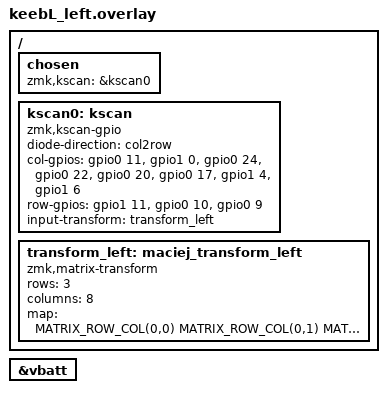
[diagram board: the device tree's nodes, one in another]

/* nice!nano v2 left half: COL2ROW, 3 rows x 8 cols */
#include <dt-bindings/zmk/matrix_transform.h>

&vbatt { status = "okay"; };

/ {
    chosen { zmk,kscan = &kscan0; }

    kscan0: kscan {
        compatible = "zmk,kscan-gpio";
        diode-direction = "col2row";

        /* Left side column pins (from KMK left col_pins) */
        col-gpios = <&gpio0 11 GPIO_ACTIVE_HIGH>,  /* P0.11 */
                    <&gpio1  0 GPIO_ACTIVE_HIGH>,  /* P1.00 */
                    <&gpio0 24 GPIO_ACTIVE_HIGH>,  /* P0.24 */
                    <&gpio0 22 GPIO_ACTIVE_HIGH>,  /* P0.22 */
                    <&gpio0 20 GPIO_ACTIVE_HIGH>,  /* P0.20 */
                    <&gpio0 17 GPIO_ACTIVE_HIGH>,  /* P0.17 */
                    <&gpio1  4 GPIO_ACTIVE_HIGH>,  /* P1.04 */
                    <&gpio1  6 GPIO_ACTIVE_HIGH>;  /* P1.06 */

        /* Left side row pins (from KMK left row_pins) */
        row-gpios = <&gpio1 11 (GPIO_ACTIVE_HIGH | GPIO_PULL_UP)>,  /* P1.11 */
                    <&gpio0 10 (GPIO_ACTIVE_HIGH | GPIO_PULL_UP)>,  /* P0.10 */
                    <&gpio0  9 (GPIO_ACTIVE_HIGH | GPIO_PULL_UP)>;  /* P0.09 */
    };
};

&kscan0 { input-transform = <&transform_left>; };

/ {
    /* Map 20 logical LEFT keys (0..5, 12..17, 24..31) to physical 3x8 */
    transform_left: maciej_transform_left {
        compatible = "zmk,matrix-transform";
        rows = <3>;
        columns = <8>;
        map = <
            /* Row1 L: logical 0..5 -> physical row0 col0..5 */
            MATRIX_ROW_COL(0,0) MATRIX_ROW_COL(0,1) MATRIX_ROW_COL(0,2)
            MATRIX_ROW_COL(0,3) MATRIX_ROW_COL(0,4) MATRIX_ROW_COL(0,5)

            /* Row2 L: logical 12..17 -> physical row1 col0..5 */
            MATRIX_ROW_COL(1,0) MATRIX_ROW_COL(1,1) MATRIX_ROW_COL(1,2)
            MATRIX_ROW_COL(1,3) MATRIX_ROW_COL(1,4) MATRIX_ROW_COL(1,5)

            /* Row3 L: logical 24..31 -> physical row2 col0..7 */
            MATRIX_ROW_COL(2,0) MATRIX_ROW_COL(2,1) MATRIX_ROW_COL(2,2) MATRIX_ROW_COL(2,3)
            MATRIX_ROW_COL(2,4) MATRIX_ROW_COL(2,5) MATRIX_ROW_COL(2,6) MATRIX_ROW_COL(2,7)
        >;
    };
};
